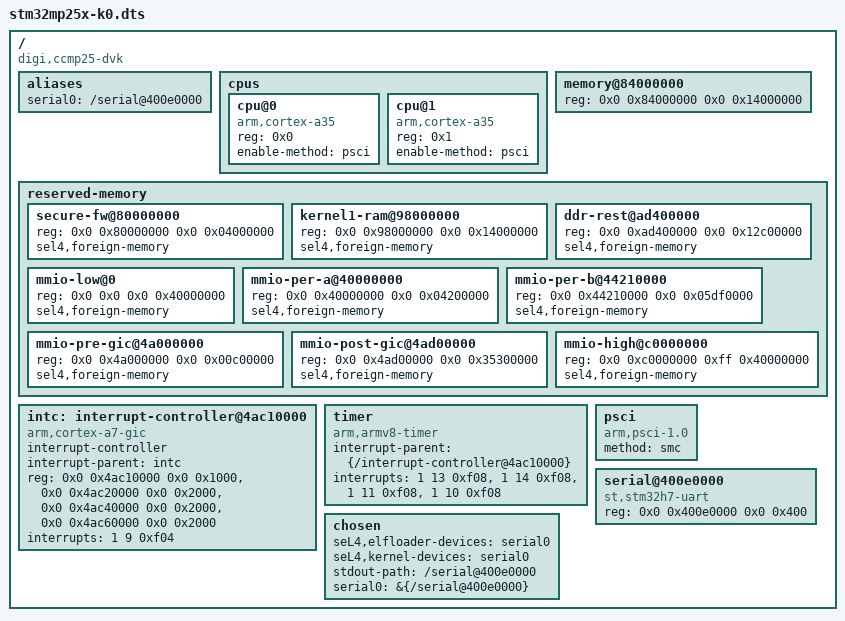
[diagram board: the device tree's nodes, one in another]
/dts-v1/;

/ {
	compatible = "digi,ccmp25-dvk", "digi,ccmp25", "st,stm32mp255";
	#address-cells = <2>;
	#size-cells = <2>;

	aliases {
		serial0 = "/serial@400e0000";
	};

	cpus {
		#address-cells = <1>;
		#size-cells = <0>;

		cpu@0 {
			compatible = "arm,cortex-a35";
			device_type = "cpu";
			reg = <0x0>;
			enable-method = "psci";
		};

		cpu@1 {
			compatible = "arm,cortex-a35";
			device_type = "cpu";
			reg = <0x1>;
			enable-method = "psci";
		};
	};

	memory@84000000 {
		device_type = "memory";
		reg = <0x0 0x84000000 0x0 0x14000000>;
	};

	/* Memory this kernel must never hand out (seL4 multikernel patch:
	 * "sel4,foreign-memory" ranges become neither RAM nor device untypeds).
	 * 0xac000000..0xad400000 (inter-kernel channel) is deliberately absent:
	 * the rootserver carves it from a device untyped. */
	reserved-memory {
		#address-cells = <2>;
		#size-cells = <2>;
		ranges;

		secure-fw@80000000 {
			reg = <0x0 0x80000000 0x0 0x04000000>;
			sel4,foreign-memory;
		};

		kernel1-ram@98000000 {
			reg = <0x0 0x98000000 0x0 0x14000000>;
			sel4,foreign-memory;
		};

		ddr-rest@ad400000 {
			reg = <0x0 0xad400000 0x0 0x12c00000>;
			sel4,foreign-memory;
		};

		/* Peripheral ownership (allow-list): reserve every MMIO range K0
		 * does not own, so it never becomes a device untyped K0 could hand
		 * to attacker code. K0 owns only RCC (0x44200000, 64 KiB); the hole
		 * below is the sole device untyped left over peripheral space.
		 * OP-TEE/IWDG are reached by SMC; the GIC (0x4ac00000..0x4ad00000)
		 * and the console UART are kernel devices left to the kernel, which
		 * already reserves their live pages. The rootserver's untyped-audit
		 * enforces the same allow-list in the image. */
		mmio-low@0 {
			reg = <0x0 0x0 0x0 0x40000000>;
			sel4,foreign-memory;
		};
		mmio-per-a@40000000 {
			reg = <0x0 0x40000000 0x0 0x04200000>; /* ..0x44200000 (RCC) */
			sel4,foreign-memory;
		};
		mmio-per-b@44210000 {
			reg = <0x0 0x44210000 0x0 0x05df0000>; /* 0x44210000..0x4a000000 */
			sel4,foreign-memory;
		};
		mmio-pre-gic@4a000000 {
			reg = <0x0 0x4a000000 0x0 0x00c00000>; /* ..0x4ac00000 (GIC area) */
			sel4,foreign-memory;
		};
		mmio-post-gic@4ad00000 {
			reg = <0x0 0x4ad00000 0x0 0x35300000>; /* 0x4ad00000..0x80000000 */
			sel4,foreign-memory;
		};
		mmio-high@c0000000 {
			reg = <0x0 0xc0000000 0xff 0x40000000>; /* 0xc0000000..0x10000000000 */
			sel4,foreign-memory;
		};
	};

	intc: interrupt-controller@4ac10000 {
		compatible = "arm,cortex-a7-gic";
		#interrupt-cells = <3>;
		interrupt-controller;
		interrupt-parent = <&intc>;
		reg = <0x0 0x4ac10000 0x0 0x1000>,
		      <0x0 0x4ac20000 0x0 0x2000>,
		      <0x0 0x4ac40000 0x0 0x2000>,
		      <0x0 0x4ac60000 0x0 0x2000>;
		interrupts = <1 9 0xf04>;
	};

	timer {
		compatible = "arm,armv8-timer";
		interrupt-parent = <&{/interrupt-controller@4ac10000}>;
		interrupts = <1 13 0xf08>,
		             <1 14 0xf08>,
		             <1 11 0xf08>,
		             <1 10 0xf08>;
	};

	psci {
		compatible = "arm,psci-1.0";
		method = "smc";
	};

	serial@400e0000 {
		compatible = "st,stm32h7-uart";
		reg = <0x0 0x400e0000 0x0 0x400>;
	};

	chosen {
		seL4,elfloader-devices =
			"serial0",
			&{/psci},
			&{/timer};

		seL4,kernel-devices =
			"serial0",
			&{/interrupt-controller@4ac10000},
			&{/timer};

		stdout-path = "/serial@400e0000";
		serial0 = &{/serial@400e0000};
	};
};
